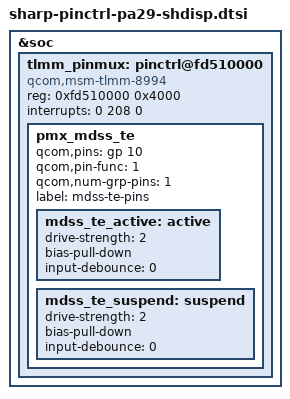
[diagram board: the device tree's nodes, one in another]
/* Copyright (c) 2015, The Linux Foundation. All rights reserved.
 *
 * This program is free software; you can redistribute it and/or modify
 * it under the terms of the GNU General Public License version 2 and
 * only version 2 as published by the Free Software Foundation.
 *
 * This program is distributed in the hope that it will be useful,
 * but WITHOUT ANY WARRANTY; without even the implied warranty of
 * MERCHANTABILITY or FITNESS FOR A PARTICULAR PURPOSE.  See the
 * GNU General Public License for more details.
 */

&soc {
	tlmm_pinmux: pinctrl@fd510000 {
		compatible = "qcom,msm-tlmm-8994", "qcom,msm-tlmm-8974";
		reg = <0xfd510000 0x4000>;
		interrupts = <0 208 0>;

		pmx_mdss_te: pmx_mdss_te {
			qcom,pins = <&gp 10>;
			qcom,pin-func = <1>;
			qcom,num-grp-pins = <1>;
			label = "mdss-te-pins";
			mdss_te_active: active {
				drive-strength = <2>; /* 2 mA */
				bias-pull-down; /* pull down*/
				input-debounce = <0>;
			};
			mdss_te_suspend: suspend {
				drive-strength = <2>; /* 2 mA */
				bias-pull-down; /* pull down*/
				input-debounce = <0>;
			};
		};
	};
};

